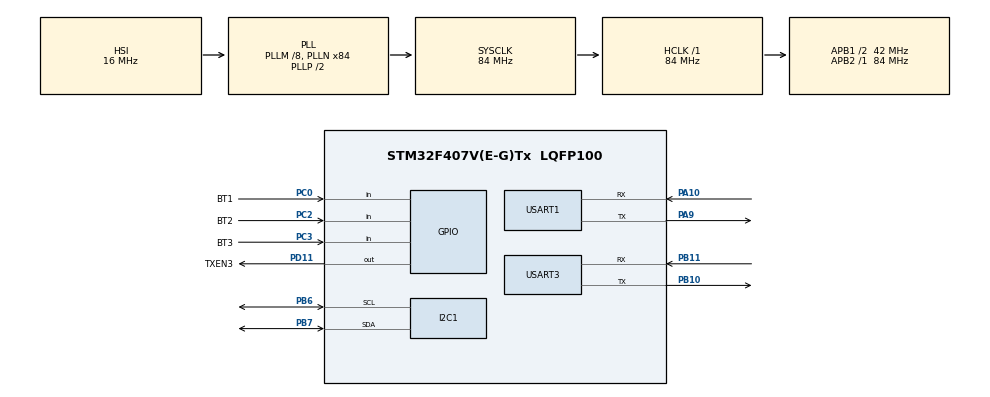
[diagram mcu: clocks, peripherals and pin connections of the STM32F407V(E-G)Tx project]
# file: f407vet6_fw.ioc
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Mcu.Family=STM32F4
Mcu.Name=STM32F407V(E-G)Tx
Mcu.Package=LQFP100
NVIC.PriorityGroup=NVIC_PRIORITYGROUP_4
PA10.Mode=Asynchronous
PA10.Signal=USART1_RX
PA13.Mode=Serial_Wire
PA13.Signal=SYS_JTMS-SWDIO
PA14.Mode=Serial_Wire
PA14.Signal=SYS_JTCK-SWCLK
PA9.Mode=Asynchronous
PA9.Signal=USART1_TX
PB10.Mode=Asynchronous
PB10.Signal=USART3_TX
PB11.Mode=Asynchronous
PB11.Signal=USART3_RX
PB6.Mode=I2C
PB6.Signal=I2C1_SCL
PB7.Mode=I2C
PB7.Signal=I2C1_SDA
PC0.GPIO_Label=BT1
PC0.GPIO_PuPd=GPIO_PULLUP
PC0.Signal=GPIO_Input
PC2.GPIO_Label=BT2
PC2.GPIO_PuPd=GPIO_PULLUP
PC2.Signal=GPIO_Input
PC3.GPIO_Label=BT3
PC3.GPIO_PuPd=GPIO_PULLUP
PC3.Signal=GPIO_Input
PD11.GPIO_Label=TXEN3
PD11.Signal=GPIO_Output
ProjectManager.HeapSize=0x200
ProjectManager.StackSize=0x400
ProjectManager.TargetToolchain=STM32CubeIDE
RCC.48MHZClocksFreq_Value=24000000
RCC.AHBFreq_Value=84000000
RCC.APB1CLKDivider=RCC_HCLK_DIV2
RCC.APB1Freq_Value=42000000
RCC.APB1TimFreq_Value=84000000
RCC.APB2Freq_Value=84000000
RCC.APB2TimFreq_Value=84000000
RCC.CortexFreq_Value=84000000
RCC.HCLKFreq_Value=84000000
RCC.HSE_VALUE=8000000
RCC.HSI_VALUE=16000000
RCC.LSE_VALUE=32768
RCC.PLLM=8
RCC.PLLN=84
RCC.PLLQ=7
RCC.SYSCLKFreq_VALUE=84000000
RCC.SYSCLKSource=RCC_SYSCLKSOURCE_PLLCLK
RCC.VCOOutputFreq_Value=168000000
USART1.VirtualMode=VM_ASYNC
USART3.VirtualMode=VM_ASYNC
board=custom

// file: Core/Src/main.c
/* USER CODE BEGIN Header */
/**
  ******************************************************************************
  * @file           : main.c
  * @brief          : Main program body
  ******************************************************************************
  * @attention
  *
  * Copyright (c) 2026 STMicroelectronics.
  * All rights reserved.
  *
  * This software is licensed under terms that can be found in the LICENSE file
  * in the root directory of this software component.
  * If no LICENSE file comes with this software, it is provided AS-IS.
  *
  ******************************************************************************
  */
/* USER CODE END Header */
#include <stdio.h>
#include "main.h"
#include "i2c.h"
#include "usart.h"
#include "gpio.h"
#include "driver/button.h"

void SystemClock_Config(void);
/* USER CODE BEGIN PFP */
int _write(int file, char *p, int len)
{
  HAL_UART_Transmit(&huart1, p, len, 10);
      return len;
}
/* USER CODE END PFP */

int main(void)
{

  /* MCU Configuration--------------------------------------------------------*/

  /* Reset of all peripherals, Initializes the Flash interface and the Systick. */
  HAL_Init();

  /* Configure the system clock */
  SystemClock_Config();

  /* USER CODE BEGIN SysInit */
  button_init();
  /* USER CODE END SysInit */

  /* Initialize all configured peripherals */
  MX_GPIO_Init();
  MX_USART1_UART_Init();
  MX_I2C1_Init();
  MX_USART3_UART_Init();

  /* Infinite loop */
  /* USER CODE BEGIN WHILE */
  while (1)
  {
    button_process();

       if(button_get_event(BUTTON_BT1)
               == BUTTON_EVENT_PRESS)
       {
           printf("BT1 Press\r\n");
       }

       if(button_get_event(BUTTON_BT2)
               == BUTTON_EVENT_PRESS)
       {
           printf("BT2 Press\r\n");
       }

       if(button_get_event(BUTTON_BT3)
               == BUTTON_EVENT_PRESS)
       {
           printf("BT3 Press\r\n");
       }
  }
    /* USER CODE END WHILE */

}

void SystemClock_Config(void)
{
  RCC_OscInitTypeDef RCC_OscInitStruct = {0};
  RCC_ClkInitTypeDef RCC_ClkInitStruct = {0};

  /** Configure the main internal regulator output voltage
  */
  __HAL_RCC_PWR_CLK_ENABLE();
  __HAL_PWR_VOLTAGESCALING_CONFIG(PWR_REGULATOR_VOLTAGE_SCALE1);

  /** Initializes the RCC Oscillators according to the specified parameters
  * in the RCC_OscInitTypeDef structure.
  */
  RCC_OscInitStruct.OscillatorType = RCC_OSCILLATORTYPE_HSI;
  RCC_OscInitStruct.HSIState = RCC_HSI_ON;
  RCC_OscInitStruct.HSICalibrationValue = RCC_HSICALIBRATION_DEFAULT;
  RCC_OscInitStruct.PLL.PLLState = RCC_PLL_ON;
  RCC_OscInitStruct.PLL.PLLSource = RCC_PLLSOURCE_HSI;
  RCC_OscInitStruct.PLL.PLLM = 8;
  RCC_OscInitStruct.PLL.PLLN = 84;
  RCC_OscInitStruct.PLL.PLLP = RCC_PLLP_DIV2;
  RCC_OscInitStruct.PLL.PLLQ = 7;
  if (HAL_RCC_OscConfig(&RCC_OscInitStruct) != HAL_OK)
  {
    Error_Handler();
  }

  /** Initializes the CPU, AHB and APB buses clocks
  */
  RCC_ClkInitStruct.ClockType = RCC_CLOCKTYPE_HCLK|RCC_CLOCKTYPE_SYSCLK
                              |RCC_CLOCKTYPE_PCLK1|RCC_CLOCKTYPE_PCLK2;
  RCC_ClkInitStruct.SYSCLKSource = RCC_SYSCLKSOURCE_PLLCLK;
  RCC_ClkInitStruct.AHBCLKDivider = RCC_SYSCLK_DIV1;
  RCC_ClkInitStruct.APB1CLKDivider = RCC_HCLK_DIV2;
  RCC_ClkInitStruct.APB2CLKDivider = RCC_HCLK_DIV1;

  if (HAL_RCC_ClockConfig(&RCC_ClkInitStruct, FLASH_LATENCY_2) != HAL_OK)
  {
    Error_Handler();
  }
}

void Error_Handler(void)
{
  __disable_irq();
  while (1)
  {
  }
}
